# RE01_256KB register map
Vendor: Renesas Electronics Corporation; Series: RE01; File version: 1.00.01
CPU: CM0PLUS r0p1, little endian, MPU, no FPU, VTOR, 2 interrupt priority bits, 32 interrupts
Registers are 8-bit, read-write, reset 0x0 unless marked. A register's access mark holds for its fields unless they carry their own. Offsets are from the block's base; [hi:lo] are bit positions; 'fields as' and 'values as' point back to an identical list.

## IWDT — Independent Watchdog Timer
Base 0x40044400
0x00 IWDTRR reset 0xFF — IWDT Refresh Register
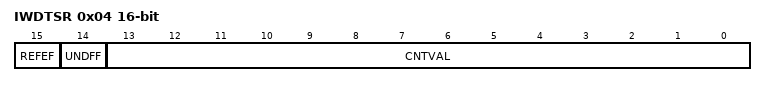
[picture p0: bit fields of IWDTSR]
0x04 IWDTSR 16-bit — IWDT Status Register
  [15] REFEF — Refresh Error Flag
    0=No refresh error occurred; 1=Refresh error occurred
  [14] UNDFF — Underflow Flag
    0=No underflow occurred; 1=Underflow occurred
  [13:0] CNTVAL ro — Down-counter Value

## CAC — Clock Frequency Accuracy Measurement Circuit
Base 0x40044600
0x00 CACR0 — CAC Control Register 0
  [0] CFME — Clock Frequency Measurement Enable
    0=Disable; 1=Enable
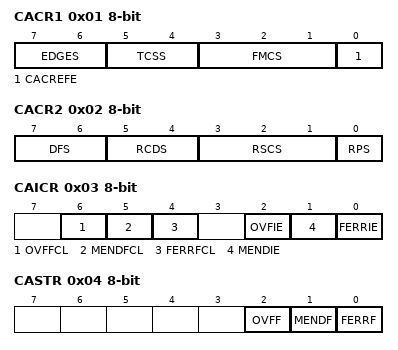
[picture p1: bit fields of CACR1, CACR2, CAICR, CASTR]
0x01 CACR1 — CAC Control Register 1
  [7:6] EDGES — Valid Edge Select
    0=Rising edge; 1=Falling edge; 2=Both rising and falling edges; 3=Setting prohibited
  [5:4] TCSS — Timer Count Clock Source Select
    0=No division; 1=x 1/4 clock; 2=x 1/8 clock; 3=x 1/32 clock
  [3:1] FMCS — Measurement Target Clock Select
    0=Main clock; 1=Sub clock; 2=HOCO clock; 3=LOCO clock; 4=IWDT-dedicated clock; 5=Peripheral module clock B (PCLKB); 6=MOCO clock; 7=CCC clock
  [0] CACREFE — CACREF Pin Input Enable
    0=Disable; 1=Enable
0x02 CACR2 — CAC Control Register 2
  [7:6] DFS — Digital Filter Select
    0=Disable digital filtering; 1=Use sampling clock for the digital filter as the frequency measuring clock; 2=Use sampling clock for the digital filter as the frequency measuring clock divided by 4; 3=Use sampling clock for the digital filter as the frequency measuring clock divided by 16
  [5:4] RCDS — Measurement Reference Clock Frequency Division Ratio Select
    0=x 1/32 clock; 1=x 1/128 clock; 2=x 1/1024 clock; 3=x 1/8192 clock
  [3:1] RSCS — Measurement Reference Clock Select
    values as CACR1.FMCS
  [0] RPS — Reference Signal Select
    0=CACREF pin input; 1=Internal clock (internally generated signal)
0x03 CAICR — CAC Interrupt Control Register
  [6] OVFFCL wo — OVFF Clear
    0=No effect; 1=The CASTR.OVFF flag is cleared
  [5] MENDFCL wo — MENDF Clear
    0=No effect; 1=The CASTR.MENDF flag is cleared
  [4] FERRFCL wo — FERRF Clear
    0=No effect; 1=The CASTR.FERRF flag is cleared
  [2] OVFIE — Overflow Interrupt Request Enable
    0=Disable; 1=Enable
  [1] MENDIE — Measurement End Interrupt Request Enable
    0=Disable; 1=Enable
  [0] FERRIE — Frequency Error Interrupt Request Enable
    0=Disable; 1=Enable
0x04 CASTR ro — CAC Status Register
  [2] OVFF — Overflow Flag
    0=Counter has not overflowed; 1=Counter overflowed
  [1] MENDF — Measurement End Flag
    0=Measurement is in progress; 1=Measurement ended
  [0] FERRF — Frequency Error Flag
    0=Clock frequency is within the allowable range; 1=Clock frequency has deviated beyond the allowable range (frequency error)
0x06 CAULVR 16-bit — CAC Upper-Limit Value Setting Register
0x08 CALLVR 16-bit — CAC Lower-Limit Value Setting Register
0x0A CACNTBR 16-bit ro — CAC Counter Buffer Register

## MSTP — Module Stop Control B, C, D
Base 0x40047000
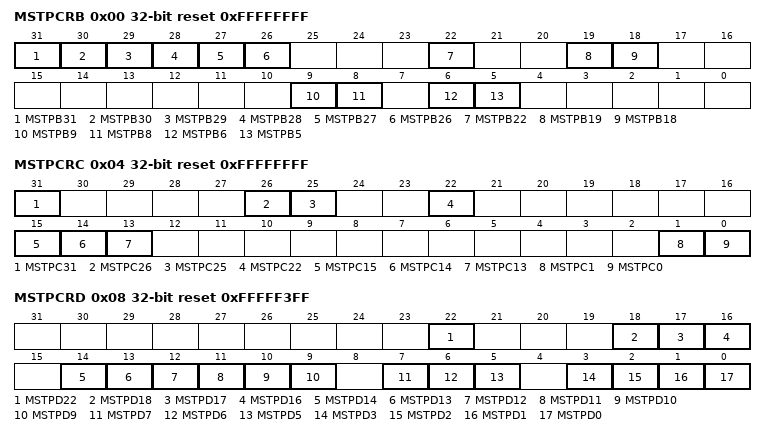
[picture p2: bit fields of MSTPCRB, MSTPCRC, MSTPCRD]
0x00 MSTPCRB 32-bit reset 0xFFFFFFFF — Module Stop Control Register B
  [all] fields
    0=Cancel the module-stop state; 1=Enter the module-stop state
  [31] MSTPB31 — SCI0 Module Stop
  [30] MSTPB30 — SCI1 Module Stop
  [29] MSTPB29 — SCI2 Module Stop
  [28] MSTPB28 — SCI3 Module Stop
  [27] MSTPB27 — SCI4 Module Stop
  [26] MSTPB26 — SCI5 Module Stop
  [22] MSTPB22 — SCI9 Module Stop
  [19] MSTPB19 — SPI0 Module Stop
  [18] MSTPB18 — SPI1 Module Stop
  [9] MSTPB9 — IIC0 Module Stop
  [8] MSTPB8 — IIC1 Module Stop
  [6] MSTPB6 — QSPI Module Stop
  [5] MSTPB5 — IrDA Module Stop
0x04 MSTPCRC 32-bit reset 0xFFFFFFFF — Module Stop Control Register C
  [all] fields
    values as the fields of MSTPCRB
  [31] MSTPC31 — TSIP-Lite Module Stop
  [26] MSTPC26 — GDT Module Stop
  [25] MSTPC25 — MLCD Module Stop
  [22] MSTPC22 — DIL Module Stop
  [15] MSTPC15 — DIV Module Stop
  [14] MSTPC14 — ELC Module Stop
  [13] MSTPC13 — DOC Module Stop
  [1] MSTPC1 — CRC Module Stop
  [0] MSTPC0 — CAC Module Stop
0x08 MSTPCRD 32-bit reset 0xFFFFF3FF — Module Stop Control Register D
  [all] fields
    values as the fields of MSTPCRB
  [22] MSTPD22 — TSN Module Stop
  [18] MSTPD18 — WUPT Module Stop
  [17] MSTPD17 — VREF Module Stop
  [16] MSTPD16 — ADC14 Module Stop
  [14] MSTPD14 — POE Module Stop
  [13] MSTPD13 — AGTW1 Module Stop
  [12] MSTPD12 — AGTW0 Module Stop
  [11] MSTPD11 — WDT Module Stop
  [10] MSTPD10 — IWDT Module Stop
  [9] MSTPD9 — RTC Module Stop
  [7] MSTPD7 — CCC Module Stop
  [6] MSTPD6 — GPT162 to GPT165 Module Stop
  [5] MSTPD5 — GPT320 and GPT321 Module Stop
  [3] MSTPD3 — AGT0 Module Stop
  [2] MSTPD2 — AGT1 Module Stop
  [1] MSTPD1 — TMR Module Stop
  [0] MSTPD0 — LST Module Stop
